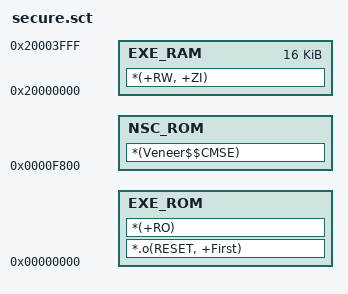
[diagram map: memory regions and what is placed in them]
    
LR_ROM 0x0 0xf800
{

    EXE_ROM +0
    {
        *.o(RESET, +First)
        *(+RO)
    }
    
    EXE_RAM 0x20000000 0x4000
    {
        *(+RW, +ZI)
    }
	
}

LR_NSC 0xf800 0x800
{
    NSC_ROM +0
    {
        *(Veneer$$CMSE)
    }
}
